# ESP32-C61 register map
Vendor: ESPRESSIF SYSTEMS (SHANGHAI) CO., LTD.; Series: ESP32 C-Series; File version: 1
CPU: RV32IMAC r0p0, little endian, no MPU, no FPU, 0 interrupt priority bits
Address unit: 32 bits
Registers are 32-bit, read-write, reset 0x0 unless marked. A register's access mark holds for its fields unless they carry their own. Offsets are from the block's base; [hi:lo] are bit positions; {n}, {i} and the like mark numbered series.

## SPI1 — SPI (Serial Peripheral Interface) Controller 1
Base 0x60003000
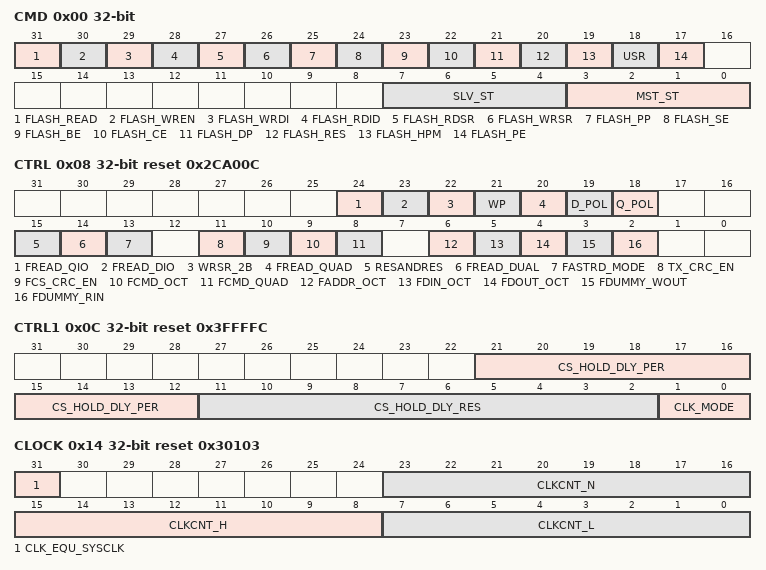
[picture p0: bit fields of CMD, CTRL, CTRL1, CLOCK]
0x00 CMD access per field — SPI1 memory command register
  [31] FLASH_READ rw — Read flash enable. Read flash operation will be triggered when the bit is set. The bit will be cleared once the operation done. 1: enable 0: disable.
  [30] FLASH_WREN rw — Write flash enable. Write enable command will be sent when the bit is set. The bit will be cleared once the operation done. 1: enable 0: disable.
  [29] FLASH_WRDI rw — Write flash disable. Write disable command will be sent when the bit is set. The bit will be cleared once the operation done. 1: enable 0: disable.
  [28] FLASH_RDID rw — Read JEDEC ID . Read ID command will be sent when the bit is set. The bit will be cleared once the operation done. 1: enable 0: disable.
  [27] FLASH_RDSR rw — Read status register-1. Read status operation will be triggered when the bit is set. The bit will be cleared once the operation done.1: enable 0: disable.
  [26] FLASH_WRSR rw — Write status register enable. Write status operation will be triggered when the bit is set. The bit will be cleared once the operation done.1: enable 0: disable.
  [25] FLASH_PP rw — Page program enable(1 byte ~256 bytes data to be programmed). Page program operation will be triggered when the bit is set. The bit will be cleared once the operation done .1: enable 0: disable.
  [24] FLASH_SE rw — Sector erase enable(4KB). Sector erase operation will be triggered when the bit is set. The bit will be cleared once the operation done.1: enable 0: disable.
  [23] FLASH_BE rw — Block erase enable(32KB) . Block erase operation will be triggered when the bit is set. The bit will be cleared once the operation done.1: enable 0: disable.
  [22] FLASH_CE rw — Chip erase enable. Chip erase operation will be triggered when the bit is set. The bit will be cleared once the operation done.1: enable 0: disable.
  [21] FLASH_DP rw — Drive Flash into power down. An operation will be triggered when the bit is set. The bit will be cleared once the operation done.1: enable 0: disable.
  [20] FLASH_RES rw — This bit combined with reg_resandres bit releases Flash from the power-down state or high performance mode and obtains the devices ID. The bit will be cleared once the operation done.1: enable 0: disable.
  [19] FLASH_HPM rw — Drive Flash into high performance mode. The bit will be cleared once the operation done.1: enable 0: disable.
  [18] USR rw — User define command enable. An operation will be triggered when the bit is set. The bit will be cleared once the operation done.1: enable 0: disable.
  [17] FLASH_PE rw — In user mode, it is set to indicate that program/erase operation will be triggered. The bit is combined with spi_mem_usr bit. The bit will be cleared once the operation done.1: enable 0: disable.
  [7:4] SLV_ST ro — The current status of SPI1 slave FSM: mspi_st. 0: idle state, 1: preparation state, 2: send command state, 3: send address state, 4: wait state, 5: read data state, 6:write data state, 7: done state, 8: read data end state.
  [3:0] MST_ST ro — The current status of SPI1 master FSM.
0x04 ADDR — SPI1 address register
  [31:0] USR_ADDR_VALUE — In user mode, it is the memory address. other then the bit0-bit23 is the memory address, the bit24-bit31 are the byte length of a transfer.
0x08 CTRL reset 0x2CA00C — SPI1 control register.
  [24] FREAD_QIO — In the read operations address phase and read-data phase apply 4 signals. 1: enable 0: disable.
  [23] FREAD_DIO — In the read operations address phase and read-data phase apply 2 signals. 1: enable 0: disable.
  [22] WRSR_2B — two bytes data will be written to status register when it is set. 1: enable 0: disable.
  [21] WP — Write protect signal output when SPI is idle. 1: output high, 0: output low.
  [20] FREAD_QUAD — In the read operations read-data phase apply 4 signals. 1: enable 0: disable.
  [19] D_POL — The bit is used to set MOSI line polarity, 1: high 0, low
  [18] Q_POL — The bit is used to set MISO line polarity, 1: high 0, low
  [15] RESANDRES — The Device ID is read out to SPI_MEM_RD_STATUS register, this bit combine with spi_mem_flash_res bit. 1: enable 0: disable.
  [14] FREAD_DUAL — In the read operations, read-data phase apply 2 signals. 1: enable 0: disable.
  [13] FASTRD_MODE — This bit enable the bits: spi_mem_fread_qio, spi_mem_fread_dio, spi_mem_fread_qout and spi_mem_fread_dout. 1: enable 0: disable.
  [11] TX_CRC_EN — For SPI1, enable crc32 when writing encrypted data to flash. 1: enable 0:disable
  [10] FCS_CRC_EN — For SPI1, initialize crc32 module before writing encrypted data to flash. Active low.
  [9] FCMD_OCT — Apply 8 signals during command phase 1:enable 0: disable
  [8] FCMD_QUAD — Apply 4 signals during command phase 1:enable 0: disable
  [6] FADDR_OCT — Apply 8 signals during address phase 1:enable 0: disable
  [5] FDIN_OCT — Apply 8 signals during read-data phase 1:enable 0: disable
  [4] FDOUT_OCT — Apply 8 signals during write-data phase 1:enable 0: disable
  [3] FDUMMY_WOUT — In the dummy phase of a MSPI write data transfer when accesses to flash, the signal level of SPI bus is output by the MSPI controller.
  [2] FDUMMY_RIN — In the dummy phase of a MSPI read data transfer when accesses to flash, the signal level of SPI bus is output by the MSPI controller.
0x0C CTRL1 reset 0x3FFFFC — SPI1 control1 register.
  [21:12] CS_HOLD_DLY_PER — After PER command is sent, SPI1 waits (SPI_MEM_CS_HOLD_DLY_PER[9:0] * 128) SPI_CLK cycles.
  [11:2] CS_HOLD_DLY_RES — After RES/DP/HPM/PES command is sent, SPI1 waits (SPI_MEM_CS_HOLD_DELAY_RES[9:0] * 128) SPI_CLK cycles.
  [1:0] CLK_MODE — SPI clock mode bits. 0: SPI clock is off when CS inactive 1: SPI clock is delayed one cycle after CS inactive 2: SPI clock is delayed two cycles after CS inactive 3: SPI clock is alwasy on.
0x10 CTRL2 wo — SPI1 control2 register.
  [31] SYNC_RESET — The FSM will be reset.
0x14 CLOCK reset 0x30103 — SPI1 clock division control register.
  [31] CLK_EQU_SYSCLK — reserved
  [23:16] CLKCNT_N — In the master mode it is the divider of spi_mem_clk. So spi_mem_clk frequency is system/(SPI_MEM_CLKCNT_N+1)
  [15:8] CLKCNT_H — In the master mode it must be floor((SPI_MEM_CLKCNT_N+1)/2-1).
  [7:0] CLKCNT_L — In the master mode it must be equal to SPI_MEM_CLKCNT_N.
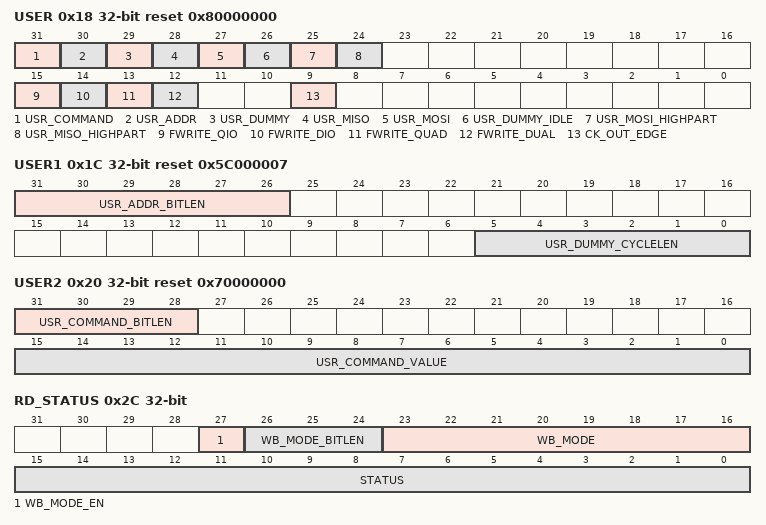
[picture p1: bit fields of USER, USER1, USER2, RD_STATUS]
0x18 USER reset 0x80000000 — SPI1 user register.
  [31] USR_COMMAND — This bit enable the command phase of an operation.
  [30] USR_ADDR — This bit enable the address phase of an operation.
  [29] USR_DUMMY — This bit enable the dummy phase of an operation.
  [28] USR_MISO — This bit enable the read-data phase of an operation.
  [27] USR_MOSI — This bit enable the write-data phase of an operation.
  [26] USR_DUMMY_IDLE — SPI clock is disable in dummy phase when the bit is enable.
  [25] USR_MOSI_HIGHPART — write-data phase only access to high-part of the buffer spi_mem_w8~spi_mem_w15. 1: enable 0: disable.
  [24] USR_MISO_HIGHPART — read-data phase only access to high-part of the buffer spi_mem_w8~spi_mem_w15. 1: enable 0: disable.
  [15] FWRITE_QIO — In the write operations address phase and read-data phase apply 4 signals.
  [14] FWRITE_DIO — In the write operations address phase and read-data phase apply 2 signals.
  [13] FWRITE_QUAD — In the write operations read-data phase apply 4 signals
  [12] FWRITE_DUAL — In the write operations read-data phase apply 2 signals
  [9] CK_OUT_EDGE — the bit combined with spi_mem_mosi_delay_mode bits to set mosi signal delay mode.
0x1C USER1 reset 0x5C000007 — SPI1 user1 register.
  [31:26] USR_ADDR_BITLEN — The length in bits of address phase. The register value shall be (bit_num-1).
  [5:0] USR_DUMMY_CYCLELEN — The length in spi_mem_clk cycles of dummy phase. The register value shall be (cycle_num-1).
0x20 USER2 reset 0x70000000 — SPI1 user2 register.
  [31:28] USR_COMMAND_BITLEN — The length in bits of command phase. The register value shall be (bit_num-1)
  [15:0] USR_COMMAND_VALUE — The value of command.
0x24 MOSI_DLEN — SPI1 send data bit length control register.
  [9:0] USR_MOSI_DBITLEN — The length in bits of write-data. The register value shall be (bit_num-1).
0x28 MISO_DLEN — SPI1 receive data bit length control register.
  [9:0] USR_MISO_DBITLEN — The length in bits of read-data. The register value shall be (bit_num-1).
0x2C RD_STATUS — SPI1 status register.
  [27] WB_MODE_EN — Mode bits is valid while this bit is enable. 1: enable 0: disable.
  [26:24] WB_MODE_BITLEN — Mode bits length for flash fast read mode.
  [23:16] WB_MODE — Mode bits in the flash fast read mode it is combined with spi_mem_fastrd_mode bit.
  [15:0] STATUS — The value is stored when set spi_mem_flash_rdsr bit and spi_mem_flash_res bit.
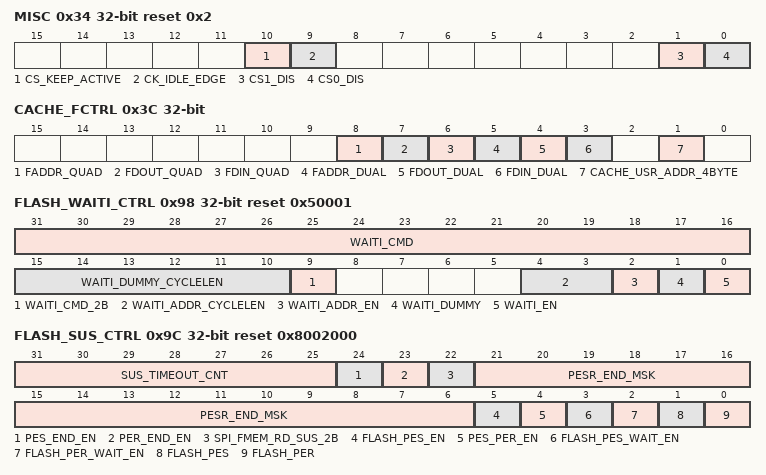
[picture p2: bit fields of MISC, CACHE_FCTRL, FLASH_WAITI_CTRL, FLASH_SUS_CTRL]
0x34 MISC reset 0x2 — SPI1 misc register
  [10] CS_KEEP_ACTIVE — spi cs line keep low when the bit is set.
  [9] CK_IDLE_EDGE — 1: spi clk line is high when idle 0: spi clk line is low when idle
  [1] CS1_DIS — SPI_CS1 pin enable, 1: disable SPI_CS1, 0: SPI_CS1 pin is active to select SPI device, such as flash, external RAM and so on.
  [0] CS0_DIS — SPI_CS0 pin enable, 1: disable SPI_CS0, 0: SPI_CS0 pin is active to select SPI device, such as flash, external RAM and so on.
0x38 TX_CRC ro reset 0xFFFFFFFF — SPI1 TX CRC data register.
  [31:0] DATA — For SPI1, the value of crc32.
0x3C CACHE_FCTRL — SPI1 bit mode control register.
  [8] FADDR_QUAD — For SPI1, address phase apply 4 signals. 1: enable 0: disable. The bit is the same with spi_mem_fread_qio.
  [7] FDOUT_QUAD — For SPI1, dout phase apply 4 signals. 1: enable 0: disable. The bit is the same with spi_mem_fread_qio.
  [6] FDIN_QUAD — For SPI1, din phase apply 4 signals. 1: enable 0: disable. The bit is the same with spi_mem_fread_qio.
  [5] FADDR_DUAL — For SPI1, address phase apply 2 signals. 1: enable 0: disable. The bit is the same with spi_mem_fread_dio.
  [4] FDOUT_DUAL — For SPI1, dout phase apply 2 signals. 1: enable 0: disable. The bit is the same with spi_mem_fread_dio.
  [3] FDIN_DUAL — For SPI1, din phase apply 2 signals. 1: enable 0: disable. The bit is the same with spi_mem_fread_dio.
  [1] CACHE_USR_ADDR_4BYTE — For SPI1, cache read flash with 4 bytes address, 1: enable, 0:disable.
{0x58+4i} W{i} (i=0..15) — SPI1 memory data buffer{i}
  [31:0] BUF{i} — data buffer
0x98 FLASH_WAITI_CTRL reset 0x50001 — SPI1 wait idle control register
  [31:16] WAITI_CMD — The command value to wait flash idle(RDSR).
  [15:10] WAITI_DUMMY_CYCLELEN — The dummy cycle length when wait flash idle(RDSR).
  [9] WAITI_CMD_2B — 1:The wait idle command bit length is 16. 0: The wait idle command bit length is 8.
  [4:3] WAITI_ADDR_CYCLELEN — When SPI_MEM_WAITI_ADDR_EN is set, the cycle length of sent out address is (SPI_MEM_WAITI_ADDR_CYCLELEN[1:0] + 1) SPI bus clock cycles. It is not active when SPI_MEM_WAITI_ADDR_EN is cleared.
  [2] WAITI_ADDR_EN — 1: Output address 0 in RDSR or read SUS command transfer. 0: Do not send out address in RDSR or read SUS command transfer.
  [1] WAITI_DUMMY — The dummy phase enable when wait flash idle (RDSR)
  [0] WAITI_EN — 1: The hardware will wait idle after SE/PP/WRSR automatically, and hardware auto Suspend/Resume can be enabled. 0: The functions of hardware wait idle and auto Suspend/Resume are not supported.
0x9C FLASH_SUS_CTRL reset 0x8002000 — SPI1 flash suspend control register
  [31:25] SUS_TIMEOUT_CNT — When SPI1 checks SUS/SUS1/SUS2 bits fail for SPI_MEM_SUS_TIMEOUT_CNT[6:0] times, it will be treated as check pass.
  [24] PES_END_EN — 1: Both WIP and SUS/SUS1/SUS2 bits should be checked to insure the suspend status of flash. 0: Only need to check WIP is 0.
  [23] PER_END_EN — 1: Both WIP and SUS/SUS1/SUS2 bits should be checked to insure the resume status of flash. 0: Only need to check WIP is 0.
  [22] SPI_FMEM_RD_SUS_2B — 1: Read two bytes when check flash SUS/SUS1/SUS2 status bit. 0: Read one byte when check flash SUS/SUS1/SUS2 status bit
  [21:6] PESR_END_MSK — The mask value when check SUS/SUS1/SUS2 status bit. If the read status value is status_in[15:0](only status_in[7:0] is valid when only one byte of data is read out, status_in[15:0] is valid when two bytes of data are read out), SUS/SUS1/SUS2 = status_in[15:0]^ SPI_MEM_PESR_END_MSK[15:0].
  [5] FLASH_PES_EN — Set this bit to enable Auto-suspending function.
  [4] PES_PER_EN — Set this bit to enable PES end triggers PER transfer option. If this bit is 0, application should send PER after PES is done.
  [3] FLASH_PES_WAIT_EN — 1: SPI1 waits (SPI_MEM_CS_HOLD_DELAY_RES[9:0] * 4 or *128) SPI_CLK cycles after program erase suspend command is sent. 0: SPI1 does not wait after program erase suspend command is sent.
  [2] FLASH_PER_WAIT_EN — 1: SPI1 waits (SPI_MEM_CS_HOLD_DELAY_RES[9:0] * 4 or *128) SPI_CLK cycles after program erase resume command is sent. 0: SPI1 does not wait after program erase resume command is sent.
  [1] FLASH_PES — program erase suspend bit, program erase suspend operation will be triggered when the bit is set. The bit will be cleared once the operation done.1: enable 0: disable.
  [0] FLASH_PER — program erase resume bit, program erase suspend operation will be triggered when the bit is set. The bit will be cleared once the operation done.1: enable 0: disable.
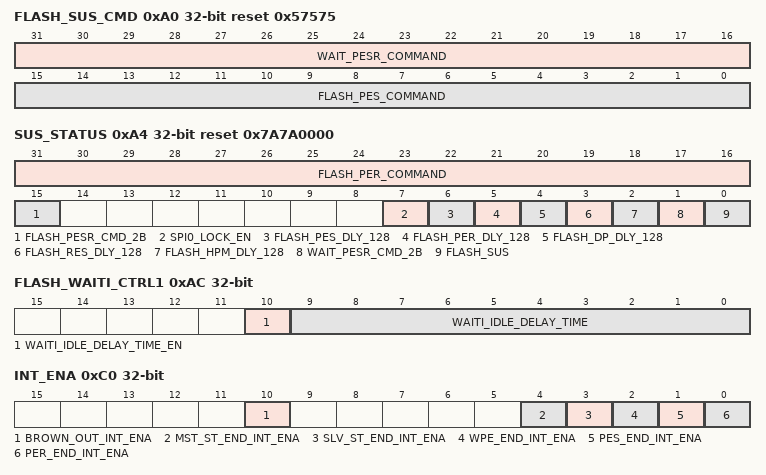
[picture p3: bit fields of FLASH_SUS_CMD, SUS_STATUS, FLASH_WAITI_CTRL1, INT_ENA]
0xA0 FLASH_SUS_CMD reset 0x57575 — SPI1 flash suspend command register
  [31:16] WAIT_PESR_COMMAND — Flash SUS/SUS1/SUS2 status bit read command. The command should be sent when SUS/SUS1/SUS2 bit should be checked to insure the suspend or resume status of flash.
  [15:0] FLASH_PES_COMMAND — Program/Erase suspend command.
0xA4 SUS_STATUS reset 0x7A7A0000 — SPI1 flash suspend status register
  [31:16] FLASH_PER_COMMAND — Program/Erase resume command.
  [15] FLASH_PESR_CMD_2B — 1: The bit length of Program/Erase Suspend/Resume command is 16. 0: The bit length of Program/Erase Suspend/Resume command is 8.
  [7] SPI0_LOCK_EN — 1: Enable SPI0 lock SPI0/1 arbiter option. 0: Disable it.
  [6] FLASH_PES_DLY_128 — Valid when SPI_MEM_FLASH_PES_WAIT_EN is 1. 1: SPI1 waits (SPI_MEM_CS_HOLD_DELAY_RES[9:0] * 128) SPI_CLK cycles after PES command is sent. 0: SPI1 waits (SPI_MEM_CS_HOLD_DELAY_RES[9:0] * 4) SPI_CLK cycles after PES command is sent.
  [5] FLASH_PER_DLY_128 — Valid when SPI_MEM_FLASH_PER_WAIT_EN is 1. 1: SPI1 waits (SPI_MEM_CS_HOLD_DELAY_RES[9:0] * 128) SPI_CLK cycles after PER command is sent. 0: SPI1 waits (SPI_MEM_CS_HOLD_DELAY_RES[9:0] * 4) SPI_CLK cycles after PER command is sent.
  [4] FLASH_DP_DLY_128 — 1: SPI1 waits (SPI_MEM_CS_HOLD_DELAY_RES[9:0] * 128) SPI_CLK cycles after DP command is sent. 0: SPI1 waits (SPI_MEM_CS_HOLD_DELAY_RES[9:0] * 4) SPI_CLK cycles after DP command is sent.
  [3] FLASH_RES_DLY_128 — 1: SPI1 waits (SPI_MEM_CS_HOLD_DELAY_RES[9:0] * 128) SPI_CLK cycles after RES command is sent. 0: SPI1 waits (SPI_MEM_CS_HOLD_DELAY_RES[9:0] * 4) SPI_CLK cycles after RES command is sent.
  [2] FLASH_HPM_DLY_128 — 1: SPI1 waits (SPI_MEM_CS_HOLD_DELAY_RES[9:0] * 128) SPI_CLK cycles after HPM command is sent. 0: SPI1 waits (SPI_MEM_CS_HOLD_DELAY_RES[9:0] * 4) SPI_CLK cycles after HPM command is sent.
  [1] WAIT_PESR_CMD_2B — 1: SPI1 sends out SPI_MEM_WAIT_PESR_COMMAND[15:0] to check SUS/SUS1/SUS2 bit. 0: SPI1 sends out SPI_MEM_WAIT_PESR_COMMAND[7:0] to check SUS/SUS1/SUS2 bit.
  [0] FLASH_SUS — The status of flash suspend, only used in SPI1.
0xAC FLASH_WAITI_CTRL1 — SPI1 wait idle control register
  [10] WAITI_IDLE_DELAY_TIME_EN — Enable SPI1 wait idle gap time count functon. 1: Enable. 0: Disable.
  [9:0] WAITI_IDLE_DELAY_TIME — SPI1 wait idle gap time configuration. SPI1 slv fsm will count during SPI1 IDLE.
0xC0 INT_ENA — SPI1 interrupt enable register
  [10] BROWN_OUT_INT_ENA — The enable bit for SPI_MEM_BROWN_OUT_INT interrupt.
  [4] MST_ST_END_INT_ENA — The enable bit for SPI_MEM_MST_ST_END_INT interrupt.
  [3] SLV_ST_END_INT_ENA — The enable bit for SPI_MEM_SLV_ST_END_INT interrupt.
  [2] WPE_END_INT_ENA — The enable bit for SPI_MEM_WPE_END_INT interrupt.
  [1] PES_END_INT_ENA — The enable bit for SPI_MEM_PES_END_INT interrupt.
  [0] PER_END_INT_ENA — The enable bit for SPI_MEM_PER_END_INT interrupt.
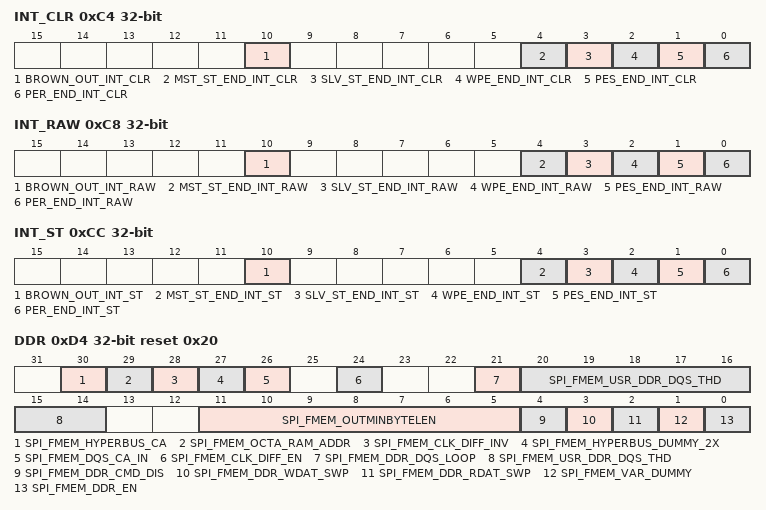
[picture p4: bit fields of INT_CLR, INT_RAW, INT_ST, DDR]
0xC4 INT_CLR wo — SPI1 interrupt clear register
  [10] BROWN_OUT_INT_CLR — The status bit for SPI_MEM_BROWN_OUT_INT interrupt.
  [4] MST_ST_END_INT_CLR — The clear bit for SPI_MEM_MST_ST_END_INT interrupt.
  [3] SLV_ST_END_INT_CLR — The clear bit for SPI_MEM_SLV_ST_END_INT interrupt.
  [2] WPE_END_INT_CLR — The clear bit for SPI_MEM_WPE_END_INT interrupt.
  [1] PES_END_INT_CLR — The clear bit for SPI_MEM_PES_END_INT interrupt.
  [0] PER_END_INT_CLR — The clear bit for SPI_MEM_PER_END_INT interrupt.
0xC8 INT_RAW — SPI1 interrupt raw register
  [10] BROWN_OUT_INT_RAW — The raw bit for SPI_MEM_BROWN_OUT_INT interrupt. 1: Triggered condition is that chip is loosing power and RTC module sends out brown out close flash request to SPI1. After SPI1 sends out suspend command to flash, this interrupt is triggered and MSPI returns to idle state. 0: Others.
  [4] MST_ST_END_INT_RAW — The raw bit for SPI_MEM_MST_ST_END_INT interrupt. 1: Triggered when spi1_mst_st is changed from non idle state to idle state. 0: Others.
  [3] SLV_ST_END_INT_RAW — The raw bit for SPI_MEM_SLV_ST_END_INT interrupt. 1: Triggered when spi1_slv_st is changed from non idle state to idle state. It means that SPI_CS raises high. 0: Others
  [2] WPE_END_INT_RAW — The raw bit for SPI_MEM_WPE_END_INT interrupt. 1: Triggered when WRSR/PP/SE/BE/CE is sent and flash is already idle. 0: Others.
  [1] PES_END_INT_RAW — The raw bit for SPI_MEM_PES_END_INT interrupt.1: Triggered when Auto Suspend command (0x75) is sent and flash is suspended successfully. 0: Others.
  [0] PER_END_INT_RAW — The raw bit for SPI_MEM_PER_END_INT interrupt. 1: Triggered when Auto Resume command (0x7A) is sent and flash is resumed successfully. 0: Others.
0xCC INT_ST ro — SPI1 interrupt status register
  [10] BROWN_OUT_INT_ST — The status bit for SPI_MEM_BROWN_OUT_INT interrupt.
  [4] MST_ST_END_INT_ST — The status bit for SPI_MEM_MST_ST_END_INT interrupt.
  [3] SLV_ST_END_INT_ST — The status bit for SPI_MEM_SLV_ST_END_INT interrupt.
  [2] WPE_END_INT_ST — The status bit for SPI_MEM_WPE_END_INT interrupt.
  [1] PES_END_INT_ST — The status bit for SPI_MEM_PES_END_INT interrupt.
  [0] PER_END_INT_ST — The status bit for SPI_MEM_PER_END_INT interrupt.
0xD4 DDR reset 0x20 — SPI1 DDR control register
  [30] SPI_FMEM_HYPERBUS_CA — Set this bit to enable HyperRAM address out when accesses to flash, which means ADDR_OUT[31:0] = {spi_usr_addr_value[19:4], 13'd0, spi_usr_addr_value[3:1]}.
  [29] SPI_FMEM_OCTA_RAM_ADDR — Set this bit to enable octa_ram address out when accesses to flash, which means ADDR_OUT[31:0] = {spi_usr_addr_value[25:4], 6'd0, spi_usr_addr_value[3:1], 1'b0}.
  [28] SPI_FMEM_CLK_DIFF_INV — Set this bit to invert SPI_DIFF when accesses to flash. .
  [27] SPI_FMEM_HYPERBUS_DUMMY_2X — Set this bit to enable the vary dummy function in SPI HyperBus mode, when SPI0 accesses flash or SPI1 accesses flash or sram.
  [26] SPI_FMEM_DQS_CA_IN — Set this bit to enable the input of SPI_DQS signal in SPI phases of CMD and ADDR.
  [24] SPI_FMEM_CLK_DIFF_EN — Set this bit to enable the differential SPI_CLK#.
  [21] SPI_FMEM_DDR_DQS_LOOP — 1: Do not need the input of SPI_DQS signal, SPI0 starts to receive data when spi0_slv_st is in SPI_MEM_DIN state. It is used when there is no SPI_DQS signal or SPI_DQS signal is not stable. 0: SPI0 starts to store data at the positive and negative edge of SPI_DQS.
  [20:14] SPI_FMEM_USR_DDR_DQS_THD — The delay number of data strobe which from memory based on SPI clock.
  [11:5] SPI_FMEM_OUTMINBYTELEN — It is the minimum output data length in the panda device.
  [4] SPI_FMEM_DDR_CMD_DIS — the bit is used to disable dual edge in command phase when ddr mode.
  [3] SPI_FMEM_DDR_WDAT_SWP — Set the bit to reorder tx data of the word in spi ddr mode.
  [2] SPI_FMEM_DDR_RDAT_SWP — Set the bit to reorder rx data of the word in spi ddr mode.
  [1] SPI_FMEM_VAR_DUMMY — Set the bit to enable variable dummy cycle in spi ddr mode.
  [0] SPI_FMEM_DDR_EN — 1: in ddr mode, 0 in sdr mode
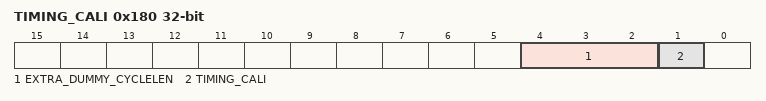
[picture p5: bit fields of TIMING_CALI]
0x180 TIMING_CALI — SPI1 timing control register
  [4:2] EXTRA_DUMMY_CYCLELEN — add extra dummy spi clock cycle length for spi clock calibration.
  [1] TIMING_CALI — The bit is used to enable timing auto-calibration for all reading operations.
0x200 CLOCK_GATE reset 0x1 — SPI1 clk_gate register
  [0] CLK_EN — Register clock gate enable signal. 1: Enable. 0: Disable.
0x3FC DATE reset 0x2412300 — Version control register
  [27:0] DATE
